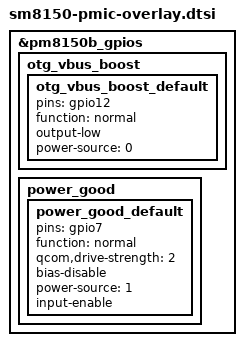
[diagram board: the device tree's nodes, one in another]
/*
 * Copyright (c) 2017-2019, The Linux Foundation. All rights reserved.
 *
 * This program is free software; you can redistribute it and/or modify
 * it under the terms of the GNU General Public License version 2 and
 * only version 2 as published by the Free Software Foundation.
 *
 * This program is distributed in the hope that it will be useful,
 * but WITHOUT ANY WARRANTY; without even the implied warranty of
 * MERCHANTABILITY or FITNESS FOR A PARTICULAR PURPOSE.  See the
 * GNU General Public License for more details.
 */

#include "../../qcom/sm8150-pmic-overlay.dtsi"

#include "pm8150.dtsi"
#include "pm8150b.dtsi"
#include "pm8150l.dtsi"

&pm8150b_gpios {
    otg_vbus_boost {
		otg_vbus_boost_default: otg_vbus_boost_default {
			pins = "gpio12";
			function = "normal";
			output-low;
			power-source = <0>;
		};
	};

	power_good {
		/*Get the DC Power Good signal*/
		power_good_default: power_good_default {
			pins = "gpio7";
			function = "normal";
			qcom,drive-strength = <2>; /* 2 MA */
			bias-disable;         /* NO pull */
			power-source = <1>;
			input-enable;
		};
	};
};
